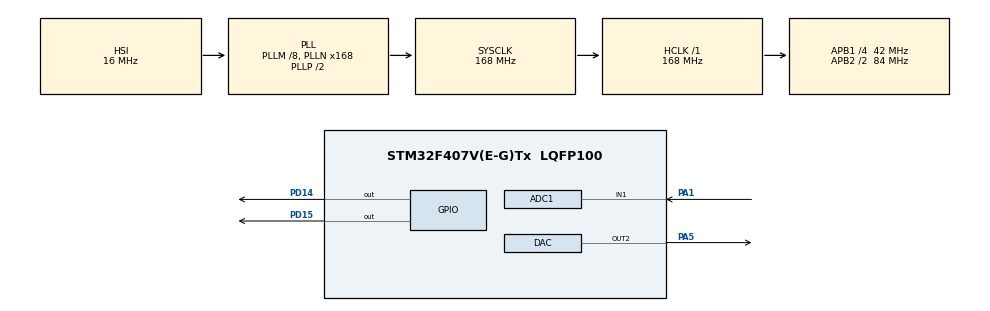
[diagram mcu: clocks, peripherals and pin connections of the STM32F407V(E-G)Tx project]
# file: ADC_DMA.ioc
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ADC1.Channel-0\#ChannelRegularConversion=ADC_CHANNEL_1
ADC1.ContinuousConvMode=DISABLE
ADC1.DMAContinuousRequests=ENABLE
ADC1.ExternalTrigConv=ADC_EXTERNALTRIGCONV_T3_TRGO
ADC1.NbrOfConversion=1
ADC1.NbrOfConversionFlag=1
ADC1.Rank-0\#ChannelRegularConversion=1
ADC1.SamplingTime-0\#ChannelRegularConversion=ADC_SAMPLETIME_56CYCLES
ADC1.ScanConvMode=DISABLE
ADC1.master=1
DAC.DAC_Trigger2=DAC_TRIGGER_NONE
Dma.ADC1.0.Direction=DMA_PERIPH_TO_MEMORY
Dma.ADC1.0.FIFOMode=DMA_FIFOMODE_DISABLE
Dma.ADC1.0.Instance=DMA2_Stream0
Dma.ADC1.0.MemDataAlignment=DMA_MDATAALIGN_HALFWORD
Dma.ADC1.0.MemInc=DMA_MINC_ENABLE
Dma.ADC1.0.Mode=DMA_CIRCULAR
Dma.ADC1.0.PeriphDataAlignment=DMA_PDATAALIGN_HALFWORD
Dma.ADC1.0.PeriphInc=DMA_PINC_DISABLE
Dma.ADC1.0.Priority=DMA_PRIORITY_LOW
Dma.Request0=ADC1
Mcu.Family=STM32F4
Mcu.Name=STM32F407V(E-G)Tx
Mcu.Package=LQFP100
NVIC.DMA2_Stream0_IRQn=true\:0\:0\:false\:false\:true\:false\:true\:true
NVIC.PriorityGroup=NVIC_PRIORITYGROUP_4
PA1.Signal=ADCx_IN1
PA5.Signal=COMP_DAC2_group
PD14.GPIO_Speed=GPIO_SPEED_FREQ_MEDIUM
PD14.Signal=GPIO_Output
PD15.GPIO_Speed=GPIO_SPEED_FREQ_MEDIUM
PD15.Signal=GPIO_Output
PH0-OSC_IN.Mode=HSE-External-Oscillator
PH0-OSC_IN.Signal=RCC_OSC_IN
PH1-OSC_OUT.Mode=HSE-External-Oscillator
PH1-OSC_OUT.Signal=RCC_OSC_OUT
ProjectManager.HeapSize=0x200
ProjectManager.StackSize=0x400
ProjectManager.TargetToolchain=STM32CubeIDE
RCC.48MHZClocksFreq_Value=84000000
RCC.AHBFreq_Value=168000000
RCC.APB1CLKDivider=RCC_HCLK_DIV4
RCC.APB1Freq_Value=42000000
RCC.APB1TimFreq_Value=84000000
RCC.APB2CLKDivider=RCC_HCLK_DIV2
RCC.APB2Freq_Value=84000000
RCC.APB2TimFreq_Value=168000000
RCC.CortexFreq_Value=168000000
RCC.HCLKFreq_Value=168000000
RCC.HSE_VALUE=8000000
RCC.HSI_VALUE=16000000
RCC.LSE_VALUE=32768
RCC.PLLM=8
RCC.PLLN=168
RCC.SYSCLKFreq_VALUE=168000000
RCC.SYSCLKSource=RCC_SYSCLKSOURCE_PLLCLK
RCC.VCOOutputFreq_Value=336000000
SH.ADCx_IN1.0=ADC1_IN1,IN1
SH.COMP_DAC2_group.0=DAC_OUT2,DAC_OUT2
TIM3.AutoReloadPreload=TIM_AUTORELOAD_PRELOAD_ENABLE
TIM3.Period=104
TIM3.Prescaler=0
TIM3.TIM_MasterOutputTrigger=TIM_TRGO_UPDATE
VP_TIM3_VS_ClockSourceINT.Mode=Internal
board=custom

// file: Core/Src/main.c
/* USER CODE BEGIN Header */
/**
  ******************************************************************************
  * @file           : main.c
  * @brief          : Main program body
  ******************************************************************************
  * @attention
  *
  * Copyright (c) 2022 STMicroelectronics.
  * All rights reserved.
  *
  * This software is licensed under terms that can be found in the LICENSE file
  * in the root directory of this software component.
  * If no LICENSE file comes with this software, it is provided AS-IS.
  *
  ******************************************************************************
  */
/* USER CODE END Header */
#include "main.h"

/* USER CODE BEGIN PD */
#define DMA_Buff_size 16
/* USER CODE END PD */

ADC_HandleTypeDef hadc1;
DMA_HandleTypeDef hdma_adc1;

DAC_HandleTypeDef hdac;

TIM_HandleTypeDef htim3;

/* USER CODE BEGIN PV */
uint16_t DMA_Buffer[16];
uint16_t storeBuff[256];
uint32_t ADC_Value=0;
/* USER CODE END PV */

void SystemClock_Config(void);
static void MX_GPIO_Init(void);
static void MX_DMA_Init(void);
static void MX_ADC1_Init(void);
static void MX_TIM3_Init(void);
static void MX_DAC_Init(void);

int main(void)
{

  /* MCU Configuration--------------------------------------------------------*/

  /* Reset of all peripherals, Initializes the Flash interface and the Systick. */
  HAL_Init();

  /* Configure the system clock */
  SystemClock_Config();

  /* Initialize all configured peripherals */
  MX_GPIO_Init();
  MX_DMA_Init();
  MX_ADC1_Init();
  MX_TIM3_Init();
  MX_DAC_Init();
  /* USER CODE BEGIN 2 */
  HAL_ADC_Start_DMA(&hadc1, (uint32_t*)DMA_Buffer, sizeof(DMA_Buffer));
  HAL_TIM_Base_Start(&htim3);
  HAL_DAC_Start(&hdac, DAC_CHANNEL_2);
  //HAL_DAC_Start_DMA(&hdac,DAC_CHANNEL_2,DMA_Buffer,16,DAC_ALIGN_12B_R);
  /* USER CODE END 2 */

  /* Infinite loop */
  while (1)
  {

  }
}

void SystemClock_Config(void)
{
  RCC_OscInitTypeDef RCC_OscInitStruct = {0};
  RCC_ClkInitTypeDef RCC_ClkInitStruct = {0};

  /** Configure the main internal regulator output voltage
  */
  __HAL_RCC_PWR_CLK_ENABLE();
  __HAL_PWR_VOLTAGESCALING_CONFIG(PWR_REGULATOR_VOLTAGE_SCALE1);

  /** Initializes the RCC Oscillators according to the specified parameters
  * in the RCC_OscInitTypeDef structure.
  */
  RCC_OscInitStruct.OscillatorType = RCC_OSCILLATORTYPE_HSI;
  RCC_OscInitStruct.HSIState = RCC_HSI_ON;
  RCC_OscInitStruct.HSICalibrationValue = RCC_HSICALIBRATION_DEFAULT;
  RCC_OscInitStruct.PLL.PLLState = RCC_PLL_ON;
  RCC_OscInitStruct.PLL.PLLSource = RCC_PLLSOURCE_HSI;
  RCC_OscInitStruct.PLL.PLLM = 8;
  RCC_OscInitStruct.PLL.PLLN = 168;
  RCC_OscInitStruct.PLL.PLLP = RCC_PLLP_DIV2;
  RCC_OscInitStruct.PLL.PLLQ = 4;
  if (HAL_RCC_OscConfig(&RCC_OscInitStruct) != HAL_OK)
  {
    Error_Handler();
  }

  /** Initializes the CPU, AHB and APB buses clocks
  */
  RCC_ClkInitStruct.ClockType = RCC_CLOCKTYPE_HCLK|RCC_CLOCKTYPE_SYSCLK
                              |RCC_CLOCKTYPE_PCLK1|RCC_CLOCKTYPE_PCLK2;
  RCC_ClkInitStruct.SYSCLKSource = RCC_SYSCLKSOURCE_PLLCLK;
  RCC_ClkInitStruct.AHBCLKDivider = RCC_SYSCLK_DIV1;
  RCC_ClkInitStruct.APB1CLKDivider = RCC_HCLK_DIV4;
  RCC_ClkInitStruct.APB2CLKDivider = RCC_HCLK_DIV2;

  if (HAL_RCC_ClockConfig(&RCC_ClkInitStruct, FLASH_LATENCY_5) != HAL_OK)
  {
    Error_Handler();
  }
}

static void MX_ADC1_Init(void)
{

  ADC_ChannelConfTypeDef sConfig = {0};

  /** Configure the global features of the ADC (Clock, Resolution, Data Alignment and number of conversion)
  */
  hadc1.Instance = ADC1;
  hadc1.Init.ClockPrescaler = ADC_CLOCK_SYNC_PCLK_DIV4;
  hadc1.Init.Resolution = ADC_RESOLUTION_12B;
  hadc1.Init.ScanConvMode = DISABLE;
  hadc1.Init.ContinuousConvMode = DISABLE;
  hadc1.Init.DiscontinuousConvMode = DISABLE;
  hadc1.Init.ExternalTrigConvEdge = ADC_EXTERNALTRIGCONVEDGE_RISING;
  hadc1.Init.ExternalTrigConv = ADC_EXTERNALTRIGCONV_T3_TRGO;
  hadc1.Init.DataAlign = ADC_DATAALIGN_RIGHT;
  hadc1.Init.NbrOfConversion = 1;
  hadc1.Init.DMAContinuousRequests = ENABLE;
  hadc1.Init.EOCSelection = ADC_EOC_SINGLE_CONV;
  if (HAL_ADC_Init(&hadc1) != HAL_OK)
  {
    Error_Handler();
  }

  /** Configure for the selected ADC regular channel its corresponding rank in the sequencer and its sample time.
  */
  sConfig.Channel = ADC_CHANNEL_1;
  sConfig.Rank = 1;
  sConfig.SamplingTime = ADC_SAMPLETIME_56CYCLES;
  if (HAL_ADC_ConfigChannel(&hadc1, &sConfig) != HAL_OK)
  {
    Error_Handler();
  }

}

static void MX_DAC_Init(void)
{

  DAC_ChannelConfTypeDef sConfig = {0};

  /** DAC Initialization
  */
  hdac.Instance = DAC;
  if (HAL_DAC_Init(&hdac) != HAL_OK)
  {
    Error_Handler();
  }

  /** DAC channel OUT2 config
  */
  sConfig.DAC_Trigger = DAC_TRIGGER_NONE;
  sConfig.DAC_OutputBuffer = DAC_OUTPUTBUFFER_ENABLE;
  if (HAL_DAC_ConfigChannel(&hdac, &sConfig, DAC_CHANNEL_2) != HAL_OK)
  {
    Error_Handler();
  }

}

static void MX_TIM3_Init(void)
{

  TIM_ClockConfigTypeDef sClockSourceConfig = {0};
  TIM_MasterConfigTypeDef sMasterConfig = {0};

  htim3.Instance = TIM3;
  htim3.Init.Prescaler = 0;
  htim3.Init.CounterMode = TIM_COUNTERMODE_UP;
  htim3.Init.Period = 104;
  htim3.Init.ClockDivision = TIM_CLOCKDIVISION_DIV1;
  htim3.Init.AutoReloadPreload = TIM_AUTORELOAD_PRELOAD_ENABLE;
  if (HAL_TIM_Base_Init(&htim3) != HAL_OK)
  {
    Error_Handler();
  }
  sClockSourceConfig.ClockSource = TIM_CLOCKSOURCE_INTERNAL;
  if (HAL_TIM_ConfigClockSource(&htim3, &sClockSourceConfig) != HAL_OK)
  {
    Error_Handler();
  }
  sMasterConfig.MasterOutputTrigger = TIM_TRGO_UPDATE;
  sMasterConfig.MasterSlaveMode = TIM_MASTERSLAVEMODE_DISABLE;
  if (HAL_TIMEx_MasterConfigSynchronization(&htim3, &sMasterConfig) != HAL_OK)
  {
    Error_Handler();
  }

}

static void MX_DMA_Init(void)
{

  /* DMA controller clock enable */
  __HAL_RCC_DMA2_CLK_ENABLE();

  /* DMA interrupt init */
  /* DMA2_Stream0_IRQn interrupt configuration */
  HAL_NVIC_SetPriority(DMA2_Stream0_IRQn, 0, 0);
  HAL_NVIC_EnableIRQ(DMA2_Stream0_IRQn);

}

static void MX_GPIO_Init(void)
{
  GPIO_InitTypeDef GPIO_InitStruct = {0};

  /* GPIO Ports Clock Enable */
  __HAL_RCC_GPIOH_CLK_ENABLE();
  __HAL_RCC_GPIOA_CLK_ENABLE();
  __HAL_RCC_GPIOD_CLK_ENABLE();

  /*Configure GPIO pin Output Level */
  HAL_GPIO_WritePin(GPIOD, GPIO_PIN_14|GPIO_PIN_15, GPIO_PIN_RESET);

  /*Configure GPIO pins : PD14 PD15 */
  GPIO_InitStruct.Pin = GPIO_PIN_14|GPIO_PIN_15;
  GPIO_InitStruct.Mode = GPIO_MODE_OUTPUT_PP;
  GPIO_InitStruct.Pull = GPIO_NOPULL;
  GPIO_InitStruct.Speed = GPIO_SPEED_FREQ_MEDIUM;
  HAL_GPIO_Init(GPIOD, &GPIO_InitStruct);

}

/* USER CODE BEGIN 4 */
void HAL_ADC_ConvCpltCallback(ADC_HandleTypeDef* hadc)
{
uint16_t ADC_Sum=0;
for(uint8_t i=0; i<DMA_Buff_size;i++){
	ADC_Sum +=DMA_Buffer[i];
	//storeBuf[i]=HAL_ADC_GetValue(hadc);
 }
static uint8_t j=0;
storeBuff[j++]=ADC_Sum;
HAL_DAC_SetValue(&hdac, DAC_CHANNEL_2, DAC_ALIGN_12B_L, ADC_Sum);
}

/* USER CODE END 4 */

void Error_Handler(void)
{
  __disable_irq();
  while (1)
  {
  }
}
